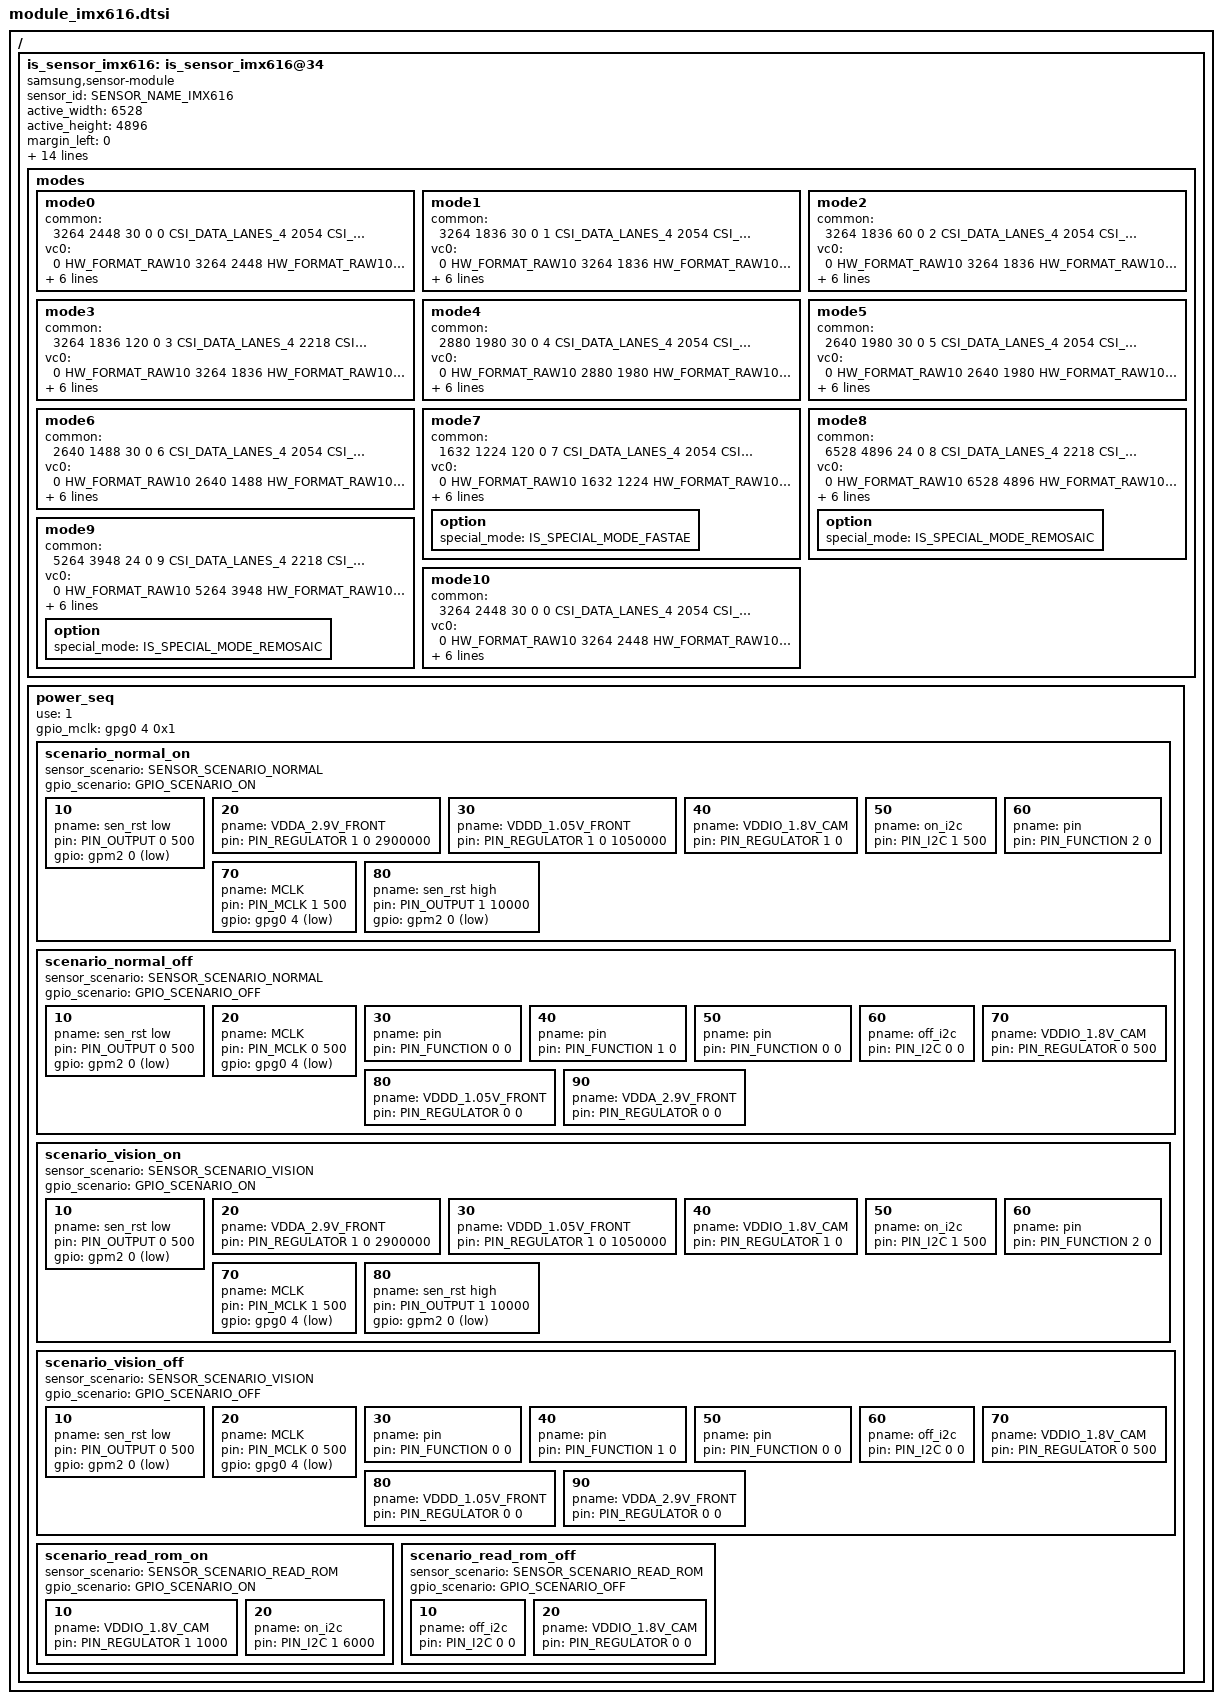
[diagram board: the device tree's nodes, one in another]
/*
 * SAMSUNG EXYNOSxxxx board camera device tree source
 *
 * Copyright (c) 2022 Samsung Electronics Co., Ltd.
 *		http://www.samsung.com
 *
 * This program is free software; you can redistribute it and/or modify
 * it under the terms of the GNU General Public License version 2 as
 * published by the Free Software Foundation.
 */

#include <dt-bindings/camera/exynos_is_dt.h>

/ {
	fragment@camera {
		target-path = "/";
		__overlay__ {
			is_sensor_imx616: is_sensor_imx616@34 {
				compatible = "samsung,sensor-module";

				/* common */
				sensor_id = <SENSOR_NAME_IMX616>;
				active_width = <6528>;
				active_height = <4896>;
				margin_left = <0>;
				margin_right = <0>;
				margin_top = <0>;
				margin_bottom = <0>;
				max_framerate = <120>;
				bitwidth = <10>;
				use_retention_mode = <SENSOR_RETENTION_INACTIVE>;
				sensor_maker = "SONY";
				sensor_name = "IMX616";
				setfile_name = "setfile_imx616.bin";
				pinning_setfile;
				preload_setfile;

				status = "okay";

				/* vendor */
				rom_type = <2>; /* ROM_TYPE_EEPROM */
				rom_id = <1>;
				rom_cal_index = <0>;
#if 0
				vc_extra {
					/* ex) statX = <stat_type, sensor_mode, max_width, max_height, max_element> */
					/* VC_BUF_DATA_TYPE_SENSOR_STAT1 */
					stat0 = </*VC_STAT_TYPE_TAIL_FOR_3HDR_IMX_2_STAT0*/ 602    /*VC_SENSOR_MODE_3HDR_IMX_2*/ 602 4080 2 1>;
					/* VC_BUF_DATA_TYPE_GENERAL_STAT1 */
					stat1 = </* not available */>;
					/* VC_BUF_DATA_TYPE_SENSOR_STAT2 */
					stat2 = </*VC_STAT_TYPE_TAIL_FOR_3HDR_IMX_2_STAT1*/ 603    /*VC_SENSOR_MODE_3HDR_IMX_2*/ 602 4080 3 1>;
					/* VC_BUF_DATA_TYPE_GENERAL_STAT2 */
					stat3 = </* not available */>;
				};
#endif
				/*
				 * [Mode Information]
				 *
				 * Reference File : IMX616-AAJH5_SAM-DPHY_26MHz_RegisterSetting_ver14.00-20.01_b1_191023.xlsx
				 *
				 * -. Global Setting -
				 *
				 * -. 2x2 BIN For Single Still Preview / Capture / Video -
				 *	[ 0 ] REG_H : 2x2 Binning 3264x2448 30fps    : Single Still Preview (4:3)     ,  MIPI lane: 4, MIPI data rate(Mbps/lane): 2054
				 *	[ 1 ] REG_I : 2x2 Binning 3264x1836 30fps    : Single Still Preview (16:9)    ,  MIPI lane: 4, MIPI data rate(Mbps/lane): 2054
				 *	[ 2 ] REG_T : 2x2 Binning 3264x1836 60fps    : Single Video (16:9)            ,  MIPI lane: 4, MIPI data rate(Mbps/lane): 2054
				 *	[ 3 ] REG_I_2 : 2x2 Binning 3264x1836 120fps : Single Video (16:9)            ,  MIPI lane: 4, MIPI data rate(Mbps/lane): 2054
				 *	[ 4 ] REG_J : 2x2 Binning 3264x1504 30fps    : Single Still Preview (19.5:9)  ,  MIPI lane: 4, MIPI data rate(Mbps/lane): 2054
				 *	[ 5 ] REG_Q : 2X2 Binning 3264x1472 30fps    : Single Still Preview (20:9)    ,  MIPI lane: 4, MIPI data rate(Mbps/lane): 2054
				 *	[ 6 ] REG_N : 2x2 Binning 2448x2448 30fps    : Single Still Preview (1:1)     ,  MIPI lane: 4, MIPI data rate(Mbps/lane): 2054
				 *	[ 7 ] REG_Y : 2x2 Binning 2144x1200 120fps   : Single Video (16:9)            ,  MIPI lane: 4, MIPI data rate(Mbps/lane): 2054
				 *
				 * -. 68 deg 2x2 BIN For Single Still Preview / Capture -
				 *	[ 8 ] REG_K : 2x2 Binning 2640x1980 30fps    : Single Still Preview (4:3)     ,  MIPI lane: 4, MIPI data rate(Mbps/lane): 2054
				 *	[ 9 ] REG_L : 2x2 Binning 2640x1488 30fps    : Single Still Preview (16:9)    ,  MIPI lane: 4, MIPI data rate(Mbps/lane): 2054
				 *	[ 10 ] REG_M : 2x2 Binning 2640x1216 30fps   : Single Still Preview (19.5:9)  ,  MIPI lane: 4, MIPI data rate(Mbps/lane): 2054
				 *	[ 11 ] REG_O_2 : 2x2 Binning 1968x1968 30fps : Single Still Preview (1:1)     ,  MIPI lane: 4, MIPI data rate(Mbps/lane): 2054
				 *
				 * -. 2x2 BIN H2V2 For FastAE
				 *	[ 12 ] REG_R_2 : 2x2 Binning 1632x1224 120fps   : FAST AE (4:3)               ,  MIPI lane: 4, MIPI data rate(Mbps/lane): 2054
				 *
				 * -. FULL Remosaic For Single Still Remosaic Capture -
				 *	[ 13 ] REG_F  : Full Remosaic 6528x4896 24fps   : Single Still Remosaic Capture (4:3) , MIPI lane: 4, MIPI data rate(Mbps/lane): 2218
				 *
				 * -. 68 deg FULL Remosaic For Single Still Remosaic Capture -
				 *	[ 14 ] REG_G : Full Remosaic 5264x3948 24fps    : Single Still Remosaic Capture (4:3) , MIPI lane: 4, MIPI data rate(Mbps/lane): 2218
				 *
				 * -. QBC HDR
				 *	[ 15 ] REG_S : QBCHDR Seamless 3264x2448 24fps  : QBCHDR seamless (4:3)        ,  MIPI lane: 4, MIPI data rate(Mbps/lane): 2218
				 *	[ 16 ] REG_W : QBCHDR Seamless 3264x1836 30fps  : QBCHDR seamless (16:9)       ,  MIPI lane: 4, MIPI data rate(Mbps/lane): 2218
				 *	[ 17 ] REG_X : 2x2Bin Seamless 3264x1836 30fps  : 2X2Bin seamless (4:3)        ,  MIPI lane: 4, MIPI data rate(Mbps/lane): 2218
				 *	[ 18 ] REG_Z : 2x2Bin Seamless 3264x2448 24fps  : 2X2Bin seamless (16:9)       ,  MIPI lane: 4, MIPI data rate(Mbps/lane): 2218
				 *
				 */

				/* sensor modes */
				modes {
						/* common = <width, height, fps, settle, mode, lane, speed, interleave, lrte, pd_mode> */
						/* vcX = <map, hwformat, width, height, hwformat, type, width, height> */

						/* 0 : 2X2BIN_3264x2448_30FPS */
						mode0 {
								common = <3264 2448 30 0 0 CSI_DATA_LANES_4 2054 CSI_MODE_DT_ONLY LRTE_DISABLE PD_NONE EX_NONE>;
								vc0 = </* in */ 0 HW_FORMAT_RAW10 3264 2448     /* out */ HW_FORMAT_RAW10 VC_NOTHING 3264 2448>;
								vc1 = </* in */ 1 HW_FORMAT_UNKNOWN 0 0         /* out */ HW_FORMAT_UNKNOWN VC_NOTHING 0 0>;
								vc2 = </* in */ 2 HW_FORMAT_UNKNOWN 0 0         /* out */ HW_FORMAT_UNKNOWN VC_NOTHING 0 0>;
								vc3 = </* in */ 3 HW_FORMAT_UNKNOWN 0 0         /* out */ HW_FORMAT_UNKNOWN VC_NOTHING 0 0>;
						};
						/* 1 : 2X2BIN_3264x1836_30FPS */
						mode1 {
								common = <3264 1836 30 0 1 CSI_DATA_LANES_4 2054 CSI_MODE_DT_ONLY LRTE_DISABLE PD_NONE EX_NONE>;
								vc0 = </* in */ 0 HW_FORMAT_RAW10 3264 1836     /* out */ HW_FORMAT_RAW10 VC_NOTHING 3264 1836>;
								vc1 = </* in */ 1 HW_FORMAT_UNKNOWN 0 0         /* out */ HW_FORMAT_UNKNOWN VC_NOTHING 0 0>;
								vc2 = </* in */ 2 HW_FORMAT_UNKNOWN 0 0         /* out */ HW_FORMAT_UNKNOWN VC_NOTHING 0 0>;
								vc3 = </* in */ 3 HW_FORMAT_UNKNOWN 0 0         /* out */ HW_FORMAT_UNKNOWN VC_NOTHING 0 0>;
						};
						/* 2 : 2X2BIN_3264x1836_60FPS */
						mode2 {
								common = <3264 1836 60 0 2 CSI_DATA_LANES_4 2054 CSI_MODE_DT_ONLY LRTE_DISABLE PD_NONE EX_NONE>;
								vc0 = </* in */ 0 HW_FORMAT_RAW10 3264 1836     /* out */ HW_FORMAT_RAW10 VC_NOTHING 3264 1836>;
								vc1 = </* in */ 1 HW_FORMAT_UNKNOWN 0 0         /* out */ HW_FORMAT_UNKNOWN VC_NOTHING 0 0>;
								vc2 = </* in */ 2 HW_FORMAT_UNKNOWN 0 0         /* out */ HW_FORMAT_UNKNOWN VC_NOTHING 0 0>;
								vc3 = </* in */ 3 HW_FORMAT_UNKNOWN 0 0         /* out */ HW_FORMAT_UNKNOWN VC_NOTHING 0 0>;
						};
						/* 3 : 2X2BIN_3264x1836_120FPS */
						mode3 {
								common = <3264 1836 120 0 3 CSI_DATA_LANES_4 2218 CSI_MODE_DT_ONLY LRTE_DISABLE PD_NONE EX_NONE>;
								vc0 = </* in */ 0 HW_FORMAT_RAW10 3264 1836     /* out */ HW_FORMAT_RAW10 VC_NOTHING 3264 1836>;
								vc1 = </* in */ 1 HW_FORMAT_UNKNOWN 0 0         /* out */ HW_FORMAT_UNKNOWN VC_NOTHING 0 0>;
								vc2 = </* in */ 2 HW_FORMAT_UNKNOWN 0 0         /* out */ HW_FORMAT_UNKNOWN VC_NOTHING 0 0>;
								vc3 = </* in */ 3 HW_FORMAT_UNKNOWN 0 0         /* out */ HW_FORMAT_UNKNOWN VC_NOTHING 0 0>;
						};
						/* 4 : 68Crop 2X2BIN_2880x1980_30FPS */
						mode4 {
								common = <2880 1980 30 0 4 CSI_DATA_LANES_4 2054 CSI_MODE_DT_ONLY LRTE_DISABLE PD_NONE EX_NONE>;
								vc0 = </* in */ 0 HW_FORMAT_RAW10 2880 1980     /* out */ HW_FORMAT_RAW10 VC_NOTHING 2880 1980>;
								vc1 = </* in */ 1 HW_FORMAT_UNKNOWN 0 0         /* out */ HW_FORMAT_UNKNOWN VC_NOTHING 0 0>;
								vc2 = </* in */ 2 HW_FORMAT_UNKNOWN 0 0         /* out */ HW_FORMAT_UNKNOWN VC_NOTHING 0 0>;
								vc3 = </* in */ 3 HW_FORMAT_UNKNOWN 0 0         /* out */ HW_FORMAT_UNKNOWN VC_NOTHING 0 0>;
						};
						/* 5 : 68Crop 2X2BIN_2640x1980_30FPS */
						mode5 {
								common = <2640 1980 30 0 5 CSI_DATA_LANES_4 2054 CSI_MODE_DT_ONLY LRTE_DISABLE PD_NONE EX_NONE>;
								vc0 = </* in */ 0 HW_FORMAT_RAW10 2640 1980     /* out */ HW_FORMAT_RAW10 VC_NOTHING 2640 1980>;
								vc1 = </* in */ 1 HW_FORMAT_UNKNOWN 0 0         /* out */ HW_FORMAT_UNKNOWN VC_NOTHING 0 0>;
								vc2 = </* in */ 2 HW_FORMAT_UNKNOWN 0 0         /* out */ HW_FORMAT_UNKNOWN VC_NOTHING 0 0>;
								vc3 = </* in */ 3 HW_FORMAT_UNKNOWN 0 0         /* out */ HW_FORMAT_UNKNOWN VC_NOTHING 0 0>;
						};
						/* 6 : 68Crop 2X2BIN_2640x1488_30FPS */
						mode6 {
								common = <2640 1488 30 0 6 CSI_DATA_LANES_4 2054 CSI_MODE_DT_ONLY LRTE_DISABLE PD_NONE EX_NONE>;
								vc0 = </* in */ 0 HW_FORMAT_RAW10 2640 1488     /* out */ HW_FORMAT_RAW10 VC_NOTHING 2640 1488>;
								vc1 = </* in */ 1 HW_FORMAT_UNKNOWN 0 0         /* out */ HW_FORMAT_UNKNOWN VC_NOTHING 0 0>;
								vc2 = </* in */ 2 HW_FORMAT_UNKNOWN 0 0         /* out */ HW_FORMAT_UNKNOWN VC_NOTHING 0 0>;
								vc3 = </* in */ 3 HW_FORMAT_UNKNOWN 0 0         /* out */ HW_FORMAT_UNKNOWN VC_NOTHING 0 0>;
						};
						/* 7 : H2V2_1632x1224_120FPS */
						mode7 {
								common = <1632 1224 120 0 7 CSI_DATA_LANES_4 2054 CSI_MODE_DT_ONLY LRTE_DISABLE PD_NONE EX_NONE>;
								vc0 = </* in */ 0 HW_FORMAT_RAW10 1632 1224     /* out */ HW_FORMAT_RAW10 VC_NOTHING 1632 1224>;
								vc1 = </* in */ 1 HW_FORMAT_UNKNOWN 0 0         /* out */ HW_FORMAT_UNKNOWN VC_NOTHING 0 0>;
								vc2 = </* in */ 2 HW_FORMAT_UNKNOWN 0 0         /* out */ HW_FORMAT_UNKNOWN VC_NOTHING 0 0>;
								vc3 = </* in */ 3 HW_FORMAT_UNKNOWN 0 0         /* out */ HW_FORMAT_UNKNOWN VC_NOTHING 0 0>;
								option { special_mode = <IS_SPECIAL_MODE_FASTAE>; };
						};
						/* 8 : REMOSAIC_6528x4896_24FPS */
						mode8 {
								common = <6528 4896 24 0 8 CSI_DATA_LANES_4 2218 CSI_MODE_DT_ONLY LRTE_DISABLE PD_NONE EX_NONE>;
								vc0 = </* in */ 0 HW_FORMAT_RAW10 6528 4896     /* out */ HW_FORMAT_RAW10 VC_NOTHING 6528 4896>;
								vc1 = </* in */ 1 HW_FORMAT_UNKNOWN 0 0         /* out */ HW_FORMAT_UNKNOWN VC_NOTHING 0 0>;
								vc2 = </* in */ 2 HW_FORMAT_UNKNOWN 0 0         /* out */ HW_FORMAT_UNKNOWN VC_NOTHING 0 0>;
								vc3 = </* in */ 3 HW_FORMAT_UNKNOWN 0 0         /* out */ HW_FORMAT_UNKNOWN VC_NOTHING 0 0>;
								option { special_mode = <IS_SPECIAL_MODE_REMOSAIC>; };
						};
						/* 9 : 68Crop REMOSAIC_5264x3948_24FPS */
						mode9 {
								common = <5264 3948 24 0 9 CSI_DATA_LANES_4 2218 CSI_MODE_DT_ONLY LRTE_DISABLE PD_NONE EX_NONE>;
								vc0 = </* in */ 0 HW_FORMAT_RAW10 5264 3948     /* out */ HW_FORMAT_RAW10 VC_NOTHING 5264 3948>;
								vc1 = </* in */ 1 HW_FORMAT_UNKNOWN 0 0         /* out */ HW_FORMAT_UNKNOWN VC_NOTHING 0 0>;
								vc2 = </* in */ 2 HW_FORMAT_UNKNOWN 0 0         /* out */ HW_FORMAT_UNKNOWN VC_NOTHING 0 0>;
								vc3 = </* in */ 3 HW_FORMAT_UNKNOWN 0 0         /* out */ HW_FORMAT_UNKNOWN VC_NOTHING 0 0>;
								option { special_mode = <IS_SPECIAL_MODE_REMOSAIC>; };
						};
						mode10 { 
								// FOR SECURE CAMERA FD SCENARIO
								common = <3264 2448 30 0 0 CSI_DATA_LANES_4 2054 CSI_MODE_VC_ONLY LRTE_DISABLE PD_NONE EX_PDSTAT_OFF>;
								vc0 = </* in */ 0 HW_FORMAT_RAW10 3264 2448	/* out */ HW_FORMAT_RAW10 VC_NOTHING 1632 1224>;
								vc1 = </* in */ 1 HW_FORMAT_UNKNOWN 0 0		/* out */ HW_FORMAT_UNKNOWN VC_NOTHING 0 0>;
								vc2 = </* in */ 2 HW_FORMAT_UNKNOWN 0 0		/* out */ HW_FORMAT_UNKNOWN VC_NOTHING 0 0>;
								vc3 = </* in */ 3 HW_FORMAT_UNKNOWN 0 0		/* out */ HW_FORMAT_UNKNOWN VC_NOTHING 0 0>;
						};
				};

				power_seq {
					use = <1>;
					gpio_mclk = <&gpg0 4 0x1>;

					scenario_normal_on {
						sensor_scenario = <SENSOR_SCENARIO_NORMAL>;
						gpio_scenario = <GPIO_SCENARIO_ON>;

						/* A start node number should be over the 10 for reserved number 0~9. */
						/* pname = "name"; pin = <act value dealy voltage>; gpio = <gpx# # 0x1>; */
						10 { pname = "sen_rst low"; pin = <PIN_OUTPUT 0 500>; gpio = <&gpm2 0 0x1>; };
						20 { pname = "VDDA_2.9V_FRONT"; pin = <PIN_REGULATOR 1 0 2900000>; };
						30 { pname = "VDDD_1.05V_FRONT"; pin = <PIN_REGULATOR 1 0 1050000>; };
						40 { pname = "VDDIO_1.8V_CAM"; pin = <PIN_REGULATOR 1 0>; };

						50 { pname = "on_i2c"; pin = <PIN_I2C 1 500>; };
						60 { pname = "pin"; pin = <PIN_FUNCTION 2 0>; };
						70 { pname = "MCLK"; pin = <PIN_MCLK 1 500>; gpio = <&gpg0 4 0x1>; };
						80 { pname = "sen_rst high"; pin = <PIN_OUTPUT 1 10000>; gpio = <&gpm2 0 0x1>; };
					};

					scenario_normal_off {
						sensor_scenario = <SENSOR_SCENARIO_NORMAL>;
						gpio_scenario = <GPIO_SCENARIO_OFF>;

						/* A start node number should be over the 10 for reserved number 0~9. */
						/* pname = "name"; pin = <act value dealy voltage>; gpio = <gpx# # 0x1>; */
						10 { pname = "sen_rst low"; pin = <PIN_OUTPUT 0 500>; gpio = <&gpm2 0 0x1>; };
						20 { pname = "MCLK"; pin = <PIN_MCLK 0 500>; gpio = <&gpg0 4 0x1>; };
						30 { pname = "pin"; pin = <PIN_FUNCTION 0 0>; };
						40 { pname = "pin"; pin = <PIN_FUNCTION 1 0>; };
						50 { pname = "pin"; pin = <PIN_FUNCTION 0 0>; };
						60 { pname = "off_i2c"; pin = <PIN_I2C 0 0>; };
						70 { pname = "VDDIO_1.8V_CAM"; pin = <PIN_REGULATOR 0 500>; };
						80 { pname = "VDDD_1.05V_FRONT"; pin = <PIN_REGULATOR 0 0>; };
						90 { pname = "VDDA_2.9V_FRONT"; pin = <PIN_REGULATOR 0 0>; };
					};
					scenario_vision_on {
						sensor_scenario = <SENSOR_SCENARIO_VISION>;
						gpio_scenario = <GPIO_SCENARIO_ON>;

						/* A start node number should be over the 10 for reserved number 0~9. */
						/* pname = "name"; pin = <act value dealy voltage>; gpio = <gpx# # 0x1>; */
						10 { pname = "sen_rst low"; pin = <PIN_OUTPUT 0 500>; gpio = <&gpm2 0 0x1>; };
						20 { pname = "VDDA_2.9V_FRONT"; pin = <PIN_REGULATOR 1 0 2900000>; };
						30 { pname = "VDDD_1.05V_FRONT"; pin = <PIN_REGULATOR 1 0 1050000>; };
						40 { pname = "VDDIO_1.8V_CAM"; pin = <PIN_REGULATOR 1 0>; };

						50 { pname = "on_i2c"; pin = <PIN_I2C 1 500>; };
						60 { pname = "pin"; pin = <PIN_FUNCTION 2 0>; };
						70 { pname = "MCLK"; pin = <PIN_MCLK 1 500>; gpio = <&gpg0 4 0x1>; };
						80 { pname = "sen_rst high"; pin = <PIN_OUTPUT 1 10000>; gpio = <&gpm2 0 0x1>; };
					};

					scenario_vision_off {
						sensor_scenario = <SENSOR_SCENARIO_VISION>;
						gpio_scenario = <GPIO_SCENARIO_OFF>;

						/* A start node number should be over the 10 for reserved number 0~9. */
						/* pname = "name"; pin = <act value dealy voltage>; gpio = <gpx# # 0x1>; */
						10 { pname = "sen_rst low"; pin = <PIN_OUTPUT 0 500>; gpio = <&gpm2 0 0x1>; };
						20 { pname = "MCLK"; pin = <PIN_MCLK 0 500>; gpio = <&gpg0 4 0x1>; };
						30 { pname = "pin"; pin = <PIN_FUNCTION 0 0>; };
						40 { pname = "pin"; pin = <PIN_FUNCTION 1 0>; };
						50 { pname = "pin"; pin = <PIN_FUNCTION 0 0>; };
						60 { pname = "off_i2c"; pin = <PIN_I2C 0 0>; };
						70 { pname = "VDDIO_1.8V_CAM"; pin = <PIN_REGULATOR 0 500>; };
						80 { pname = "VDDD_1.05V_FRONT"; pin = <PIN_REGULATOR 0 0>; };
						90 { pname = "VDDA_2.9V_FRONT"; pin = <PIN_REGULATOR 0 0>; };
					};

					scenario_read_rom_on {
						sensor_scenario = <SENSOR_SCENARIO_READ_ROM>;
						gpio_scenario = <GPIO_SCENARIO_ON>;

						/* A start node number should be over the 10 for reserved number 0~9. */
						/* pname = "name"; pin = <act value dealy voltage>; gpio = <gpx# # 0x1>; */
						10 { pname = "VDDIO_1.8V_CAM"; pin = <PIN_REGULATOR 1 1000>; };
						20 { pname = "on_i2c"; pin = <PIN_I2C 1 6000>; };
					};

					scenario_read_rom_off {
						sensor_scenario = <SENSOR_SCENARIO_READ_ROM>;
						gpio_scenario = <GPIO_SCENARIO_OFF>;

						/* A start node number should be over the 10 for reserved number 0~9. */
						/* pname = "name"; pin = <act value dealy voltage>; gpio = <gpx# # 0x1>; */
						10 { pname = "off_i2c"; pin = <PIN_I2C 0 0>; };
						20 { pname = "VDDIO_1.8V_CAM"; pin = <PIN_REGULATOR 0 0>; };
					};
				};
			};
		}; /* end of __overlay__ */
	}; /* end of fragment */
}; /* end of root */
